# mc200 register map
Registers are 32-bit, access not given, no defined reset value unless marked. A register's access mark holds for its fields unless they carry their own. Addresses are absolute; registers are grouped by the start of their names; [hi:lo] are bit positions; {n}, {i} and the like mark numbered series.

## SDIO
0x44002000 SDIO_MM4_SYSADDR
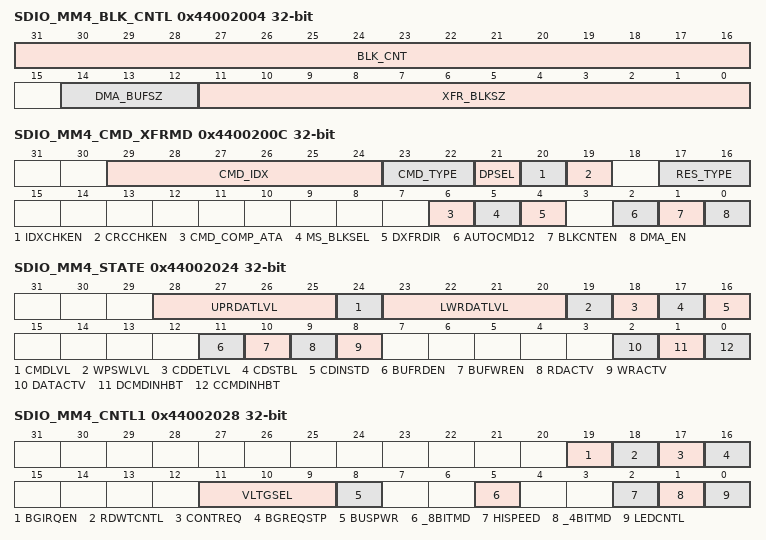
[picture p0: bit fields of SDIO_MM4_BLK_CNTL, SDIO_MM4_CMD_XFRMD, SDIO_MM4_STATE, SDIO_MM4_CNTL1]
0x44002004 SDIO_MM4_BLK_CNTL
  [31:16] BLK_CNT, [14:12] DMA_BUFSZ, [11:0] XFR_BLKSZ
0x44002008 SDIO_MM4_ARG
0x4400200C SDIO_MM4_CMD_XFRMD
  [29:24] CMD_IDX, [23:22] CMD_TYPE, [21] DPSEL, [20] IDXCHKEN, [19] CRCCHKEN, [17:16] RES_TYPE, [6] CMD_COMP_ATA, [5] MS_BLKSEL, [4] DXFRDIR, [2] AUTOCMD12, [1] BLKCNTEN, [0] DMA_EN
{0x44002010+4i} SDIO_MM4_RESP{i} (i=0..3)
  [31:0] RESP_{32i+31}_{32i}
0x44002020 SDIO_MM4_DP
  [31:0] BFR_DATA
0x44002024 SDIO_MM4_STATE
  [28:25] UPRDATLVL, [24] CMDLVL, [23:20] LWRDATLVL, [19] WPSWLVL, [18] CDDETLVL, [17] CDSTBL, [16] CDINSTD, [11] BUFRDEN, [10] BUFWREN, [9] RDACTV, [8] WRACTV, [2] DATACTV, [1] DCMDINHBT, [0] CCMDINHBT
0x44002028 SDIO_MM4_CNTL1
  [19] BGIRQEN, [18] RDWTCNTL, [17] CONTREQ, [16] BGREQSTP, [11:9] VLTGSEL, [8] BUSPWR, [5] _8BITMD, [2] HISPEED, [1] _4BITMD, [0] LEDCNTL
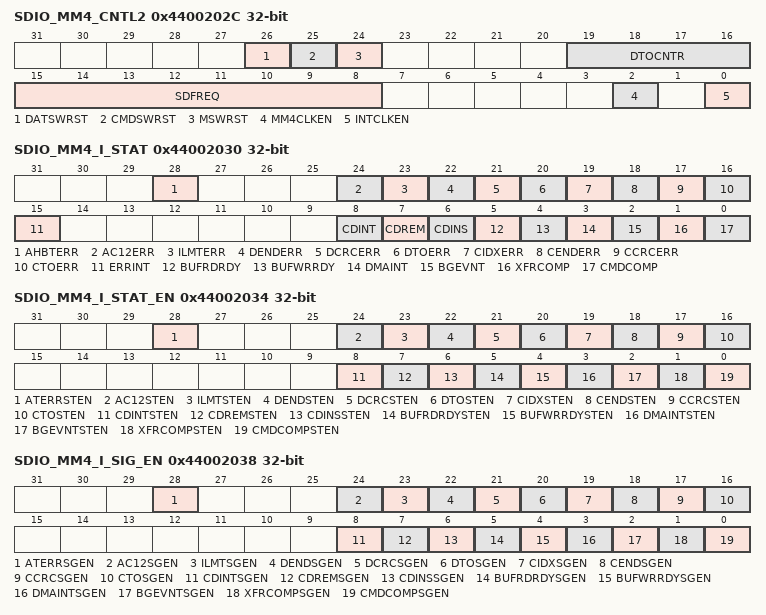
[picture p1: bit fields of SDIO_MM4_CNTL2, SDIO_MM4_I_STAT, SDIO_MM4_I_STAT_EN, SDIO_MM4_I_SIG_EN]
0x4400202C SDIO_MM4_CNTL2
  [26] DATSWRST, [25] CMDSWRST, [24] MSWRST, [19:16] DTOCNTR, [15:8] SDFREQ, [2] MM4CLKEN, [0] INTCLKEN
0x44002030 SDIO_MM4_I_STAT
  [28] AHBTERR, [24] AC12ERR, [23] ILMTERR, [22] DENDERR, [21] DCRCERR, [20] DTOERR, [19] CIDXERR, [18] CENDERR, [17] CCRCERR, [16] CTOERR, [15] ERRINT, [8] CDINT, [7] CDREM, [6] CDINS, [5] BUFRDRDY, [4] BUFWRRDY, [3] DMAINT, [2] BGEVNT, [1] XFRCOMP, [0] CMDCOMP
0x44002034 SDIO_MM4_I_STAT_EN
  [28] ATERRSTEN, [24] AC12STEN, [23] ILMTSTEN, [22] DENDSTEN, [21] DCRCSTEN, [20] DTOSTEN, [19] CIDXSTEN, [18] CENDSTEN, [17] CCRCSTEN, [16] CTOSTEN, [8] CDINTSTEN, [7] CDREMSTEN, [6] CDINSSTEN, [5] BUFRDRDYSTEN, [4] BUFWRRDYSTEN, [3] DMAINTSTEN, [2] BGEVNTSTEN, [1] XFRCOMPSTEN, [0] CMDCOMPSTEN
0x44002038 SDIO_MM4_I_SIG_EN
  [28] ATERRSGEN, [24] AC12SGEN, [23] ILMTSGEN, [22] DENDSGEN, [21] DCRCSGEN, [20] DTOSGEN, [19] CIDXSGEN, [18] CENDSGEN, [17] CCRCSGEN, [16] CTOSGEN, [8] CDINTSGEN, [7] CDREMSGEN, [6] CDINSSGEN, [5] BUFRDRDYSGEN, [4] BUFWRRDYSGEN, [3] DMAINTSGEN, [2] BGEVNTSGEN, [1] XFRCOMPSGEN, [0] CMDCOMPSGEN
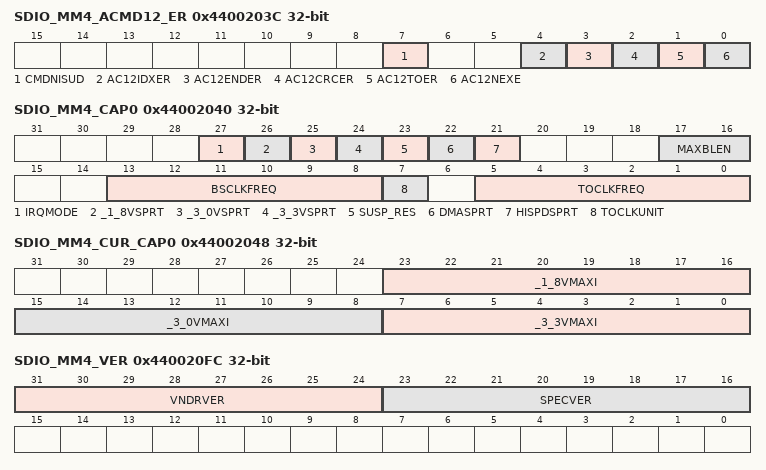
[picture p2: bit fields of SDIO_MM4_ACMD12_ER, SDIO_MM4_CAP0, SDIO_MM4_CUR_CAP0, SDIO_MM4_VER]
0x4400203C SDIO_MM4_ACMD12_ER
  [7] CMDNISUD, [4] AC12IDXER, [3] AC12ENDER, [2] AC12CRCER, [1] AC12TOER, [0] AC12NEXE
0x44002040 SDIO_MM4_CAP0
  [27] IRQMODE, [26] _1_8VSPRT, [25] _3_0VSPRT, [24] _3_3VSPRT, [23] SUSP_RES, [22] DMASPRT, [21] HISPDSPRT, [17:16] MAXBLEN, [13:8] BSCLKFREQ, [7] TOCLKUNIT, [5:0] TOCLKFREQ
0x44002048 SDIO_MM4_CUR_CAP0
  [23:16] _1_8VMAXI, [15:8] _3_0VMAXI, [7:0] _3_3VMAXI
0x440020FC SDIO_MM4_VER
  [31:24] VNDRVER, [23:16] SPECVER

## FLASHC
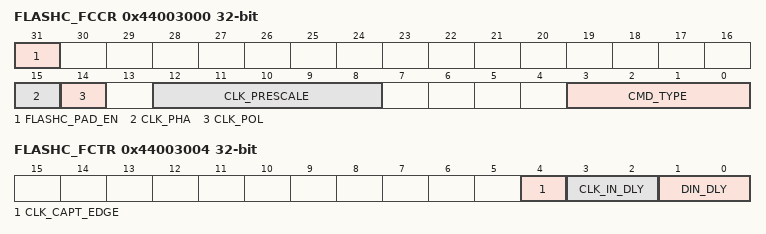
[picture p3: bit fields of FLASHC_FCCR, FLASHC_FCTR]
0x44003000 FLASHC_FCCR
  [31] FLASHC_PAD_EN, [15] CLK_PHA, [14] CLK_POL, [12:8] CLK_PRESCALE, [3:0] CMD_TYPE
0x44003004 FLASHC_FCTR
  [4] CLK_CAPT_EDGE, [3:2] CLK_IN_DLY, [1:0] DIN_DLY
0x44003008 FLASHC_FCSR
  [0] CONT_RD_MD_EXIT_DONE

## AES
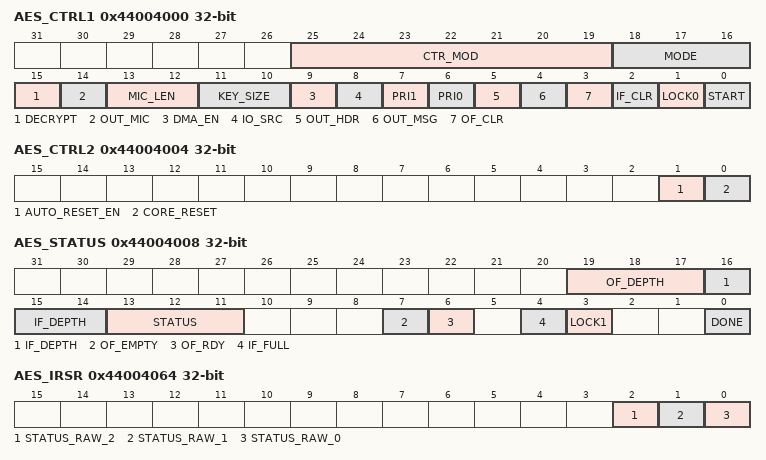
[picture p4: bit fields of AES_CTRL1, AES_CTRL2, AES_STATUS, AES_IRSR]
0x44004000 AES_CTRL1
  [25:19] CTR_MOD, [18:16] MODE, [15] DECRYPT, [14] OUT_MIC, [13:12] MIC_LEN, [11:10] KEY_SIZE, [9] DMA_EN, [8] IO_SRC, [7] PRI1, [6] PRI0, [5] OUT_HDR, [4] OUT_MSG, [3] OF_CLR, [2] IF_CLR, [1] LOCK0, [0] START
0x44004004 AES_CTRL2
  [1] AUTO_RESET_EN, [0] CORE_RESET
0x44004008 AES_STATUS
  [19:17] OF_DEPTH, [16:14] IF_DEPTH, [13:11] STATUS, [7] OF_EMPTY, [6] OF_RDY, [4] IF_FULL, [3] LOCK1, [0] DONE
0x4400400C AES_ASTR_LEN
  [31:0] ASTR_LEN
0x44004010 AES_MSTR_LEN
  [31:0] MSTR_LEN
0x44004014 AES_STR_IN
  [31:0] STR_IN
{0x44004018+4i} AES_IV{i} (i=0..3)
{0x44004028+4i} AES_KEY{i} (i=0..7)
0x44004048 AES_STR_OUT
  [31:0] STR_OUT
{0x4400404C+4i} AES_OV{i} (i=0..3)
0x4400405C AES_ISR
  [2:0] STATUS
0x44004060 AES_IMR
  [2:0] MASK
0x44004064 AES_IRSR
  [2] STATUS_RAW_2, [1] STATUS_RAW_1, [0] STATUS_RAW_0
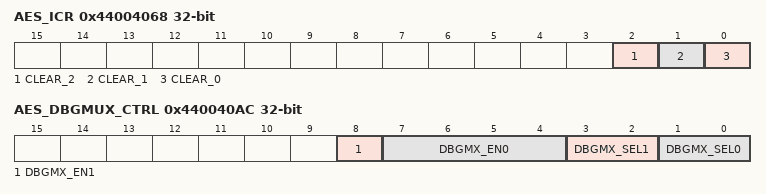
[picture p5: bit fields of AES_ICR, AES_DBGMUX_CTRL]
0x44004068 AES_ICR
  [2] CLEAR_2, [1] CLEAR_1, [0] CLEAR_0
0x44004090 AES_DBG0
  [2:0] DBG_STATUS
{0x44004090+4i} AES_DBG{i} (i=1..4)
  [31:0] DBG_B0_{i-1}
0x440040A4 AES_DBG5
  [31:0] DBG_LA_0
0x440040A8 AES_DBG6
  [15:0] DBG_LA_1
0x440040AC AES_DBGMUX_CTRL
  [8] DBGMX_EN1, [7:4] DBGMX_EN0, [3:2] DBGMX_SEL1, [1:0] DBGMX_SEL0
